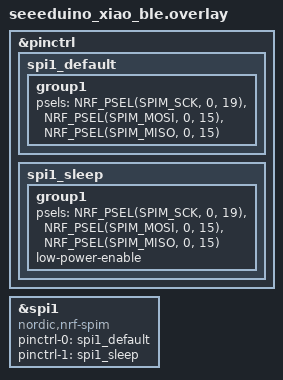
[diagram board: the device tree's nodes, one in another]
&pinctrl {
    spi1_default: spi1_default {
        group1 {
            psels = <NRF_PSEL(SPIM_SCK, 0, 19)>,
                <NRF_PSEL(SPIM_MOSI, 0, 15)>,
                <NRF_PSEL(SPIM_MISO, 0, 15)>;
        };
    };
    spi1_sleep: spi1_sleep {
        group1 {
            psels = <NRF_PSEL(SPIM_SCK, 0, 19)>,
                <NRF_PSEL(SPIM_MOSI, 0, 15)>,
                <NRF_PSEL(SPIM_MISO, 0, 15)>;
            low-power-enable;
        };
    };
};

// Trackball SPI; enabled in skreecustom_right.overlay only
&spi1 {
    compatible = "nordic,nrf-spim";
    pinctrl-0 = <&spi1_default>;
    pinctrl-1 = <&spi1_sleep>;
    pinctrl-names = "default", "sleep";
};
